# WUGEN register map
Vendor: Texas Instruments
Peripheral module from a debugger description file (folder omap36xx).
Registers are 32-bit, read-only, reset 0x0 unless marked. A register's access mark holds for its fields unless they carry their own. Offsets are as the file gives them; lines under a group give offsets from that group; [hi:lo] are bit positions; {n}, {i} and the like mark numbered series; 'fields as' and 'values as' point back to an identical list; <NAME> marks a mode.

## WUGEN
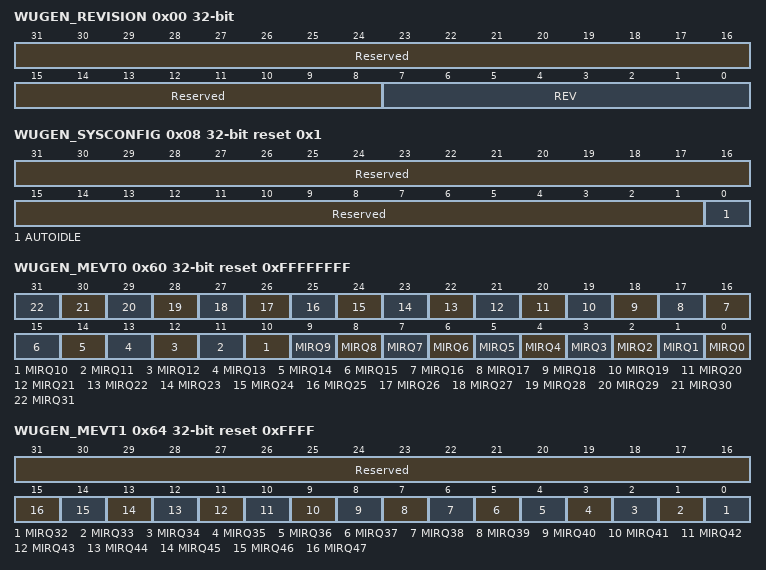
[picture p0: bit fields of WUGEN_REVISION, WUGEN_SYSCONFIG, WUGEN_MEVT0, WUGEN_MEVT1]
0x00 WUGEN_REVISION (reset mask 0xFFFFFF00) — This register contains the IP revision code
  [31:8] Reserved — Read returns 0.
  [7:0] REV — IP revision3:0 Minor revision7:4 Major revision
0x08 WUGEN_SYSCONFIG rw reset 0x1 — This register allows controlling various parameters of the WUGEN module
  [31:1] Reserved — Write 0s for future compatibility.Read returns 0.
  [0] AUTOIDLE — Internal auto-clock gating strategy0: Clock is free running1: Automatic clock gating strategy is applied
0x60 WUGEN_MEVT0 reset 0xFFFFFFFF — This register contains the interrupt mask (LSB)
  [n] MIRQ{n} (n=0..31) — Interrupt Mask bit #{n}
0x64 WUGEN_MEVT1 reset 0xFFFF — This register contains the interrupt mask (MSB)
  [31:16] Reserved — Read returns 0.
  [n-32] MIRQ{n} (n=32..47) — Interrupt Mask bit #{n}
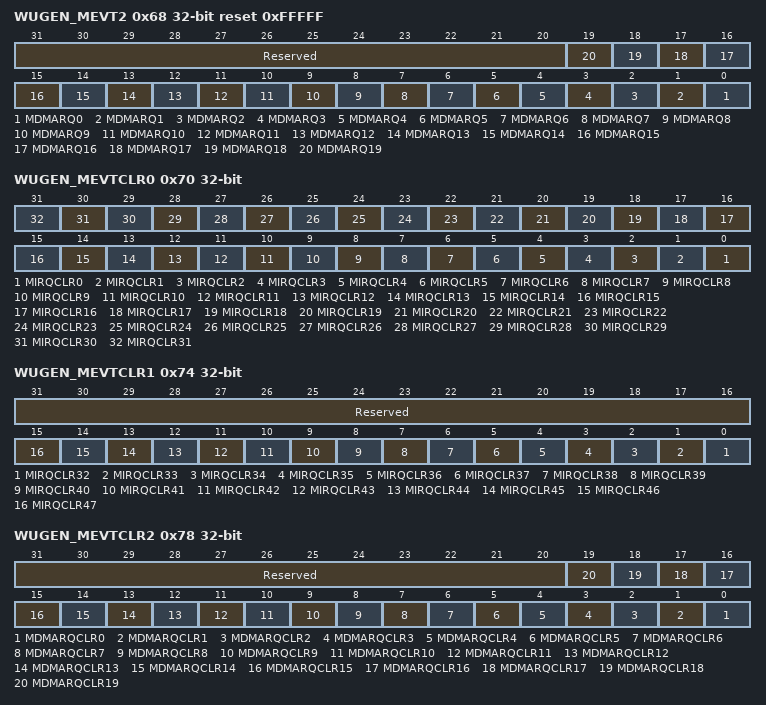
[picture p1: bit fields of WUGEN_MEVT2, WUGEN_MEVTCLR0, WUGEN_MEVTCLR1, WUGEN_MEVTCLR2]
0x68 WUGEN_MEVT2 reset 0xFFFFF — This register contains the dma request mask
  [31:20] Reserved — Read returns 0.
  [n] MDMARQ{n} (n=0..19) — DMA request Mask bit #{n}
0x70 WUGEN_MEVTCLR0 access not given — This register is used to clear the interrupt mask bits (LSB)Write 0: No effectWrite 1: Clears the corresponding mask bit in the registerReads always return 0
  [n] MIRQCLR{n} (n=0..31) — MIRQ clear #{n} (access W1toSet)
0x74 WUGEN_MEVTCLR1 access not given — This register is used to clear the interrupt mask bits (MSB)Write 0: No effectWrite 1: Clears the corresponding mask bit in the registerReads always return 0
  [31:16] Reserved wo — Write 0s for future compatibility.
  [n-32] MIRQCLR{n} (n=32..47) — MIRQ clear #{n} (access W1toSet)
0x78 WUGEN_MEVTCLR2 access not given — This register is used to clear the dma request mask bitsWrite 0: No effectWrite 1: Clears the corresponding mask bit in the registerReads always return 0
  [31:20] Reserved wo — Write 0s for future compatibility.
  [n] MDMARQCLR{n} (n=0..19) — MDMARQ clear #{n} (access W1toSet)
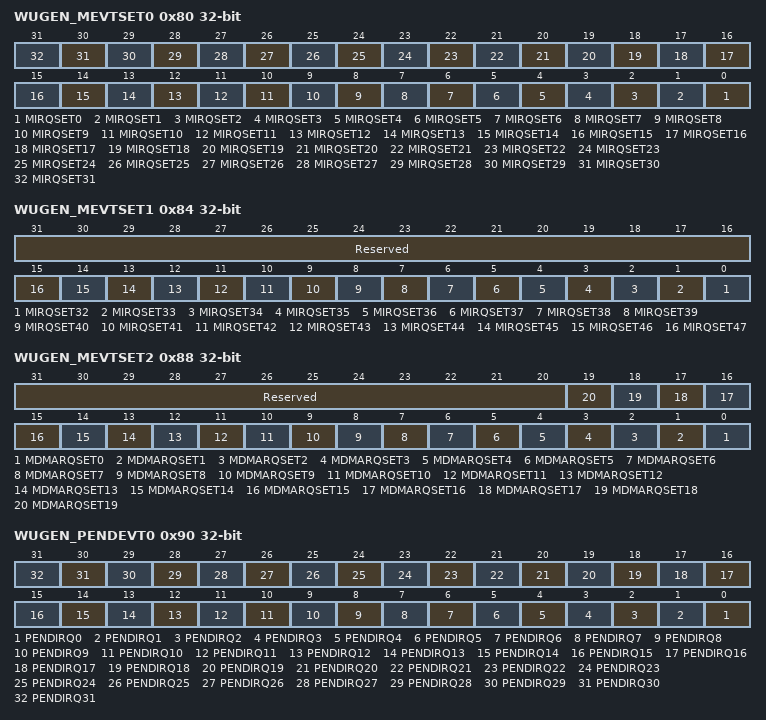
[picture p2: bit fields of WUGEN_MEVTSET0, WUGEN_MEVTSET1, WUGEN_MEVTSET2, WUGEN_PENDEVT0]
0x80 WUGEN_MEVTSET0 access not given — This register is used to set the interrupt mask bits (LSB)Write 0: No effectWrite 1: Sets the corresponding mask bit in the registerReads always return 0
  [n] MIRQSET{n} (n=0..31) — MIRQ set #{n} (access W1toSet)
0x84 WUGEN_MEVTSET1 access not given — This register is used to set the interrupt mask bits (MSB)Write 0: No effectWrite 1: Sets the corresponding mask bit in the registerReads always return 0
  [31:16] Reserved wo — Write 0s for future compatibility.
  [n-32] MIRQSET{n} (n=32..47) — MIRQ set #{n} (access W1toSet)
0x88 WUGEN_MEVTSET2 access not given — This register is used to set the dma requests mask bitsWrite 0: No effectWrite 1: Sets the corresponding mask bit in the registerReads always return 0
  [31:20] Reserved wo — Write 0s for future compatibility.
  [n] MDMARQSET{n} (n=0..19) — MDMARQ set #{n} (access W1toSet)
0x90 WUGEN_PENDEVT0 — This register holds the masked pending interrupts (LSB)
  [n] PENDIRQ{n} (n=0..31) — Masked pending interrupt number {n}
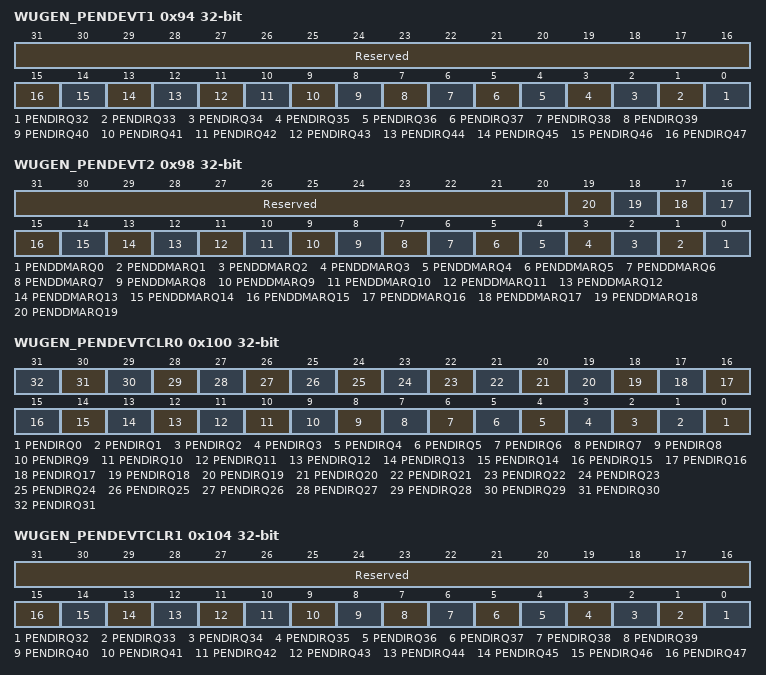
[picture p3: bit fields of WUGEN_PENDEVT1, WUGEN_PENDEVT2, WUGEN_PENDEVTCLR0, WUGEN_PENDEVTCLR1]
0x94 WUGEN_PENDEVT1 — This register holds the masked pending interrupts (MSB)
  [31:16] Reserved — Read returns 0.
  [n-32] PENDIRQ{n} (n=32..47) — Masked pending interrupt number {n}
0x98 WUGEN_PENDEVT2 — This register holds the masked pending dma requests
  [31:20] Reserved — Read returns 0.
  [n] PENDDMARQ{n} (n=0..19) — Masked pending dma request number 0
0x100 WUGEN_PENDEVTCLR0 wo — This register clears the masked pending interrupts (LSB):Write 0: No effectWrite 1: Clears the corresponding mask bit in the registerReads always return 0
  [n] PENDIRQ{n} (n=0..31) — Masked pending interrupt number {n}
0x104 WUGEN_PENDEVTCLR1 wo — This register clears the masked pending interrupts (MSB) :Write 0: No effectWrite 1: Clears the corresponding mask bit in the registerReads always return 0
  [31:16] Reserved — Write 0s for future compatibility.
  [n-32] PENDIRQ{n} (n=32..47) — Masked pending interrupt number {n}
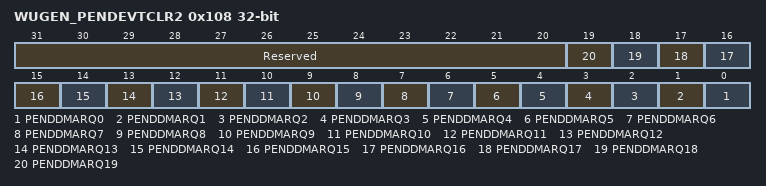
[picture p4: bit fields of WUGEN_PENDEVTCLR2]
0x108 WUGEN_PENDEVTCLR2 wo — This register clears the masked pending dma_requests:Write 0: No effectWrite 1: Clears the corresponding mask bit in the registerReads always return 0
  [31:20] Reserved — Write 0s for future compatibility.
  [n] PENDDMARQ{n} (n=0..19) — Masked pending dma request number 0
